# STM32H723 register map
File version: 1.6
CPU: CM7 r0p1, little endian, MPU, FPU, 4 interrupt priority bits
Registers are 32-bit, read-write, reset 0x0 unless marked. A register's access mark holds for its fields unless they carry their own. Offsets are from the block's base; [hi:lo] are bit positions; 'fields as' and 'values as' point back to an identical list.

## OTG1_HS_GLOBAL — USB 1 on the go high speed
Base 0x40040000
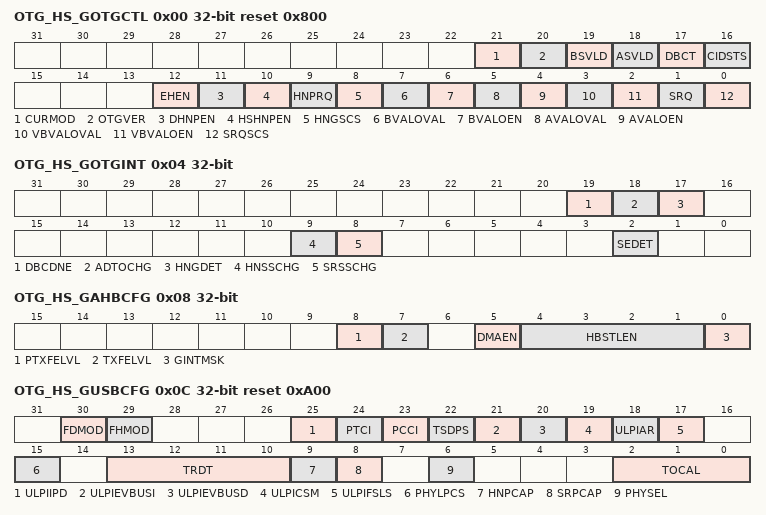
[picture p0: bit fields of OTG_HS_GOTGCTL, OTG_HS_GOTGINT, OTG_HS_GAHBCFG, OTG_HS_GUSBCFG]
0x00 OTG_HS_GOTGCTL access per field reset 0x800 — OTG_HS control and status register
  [21] CURMOD ro — Current mode of operation Indicates the current mode (host or device).
    0=Device mode; 1=Host mode
  [20] OTGVER rw — OTG version Selects the OTG revision.
    0=OTG Version 1.3. OTG1.3 is obsolete for new product development.; 1=OTG Version 2.0. In this version the core supports only data line pulsing for SRP.
  [19] BSVLD ro — B-session valid Indicates the device mode transceiver status. In OTG mode, the user can use this bit to determine if the device is connected or disconnected. Note: Only accessible in device mode.
    0=B-session is not valid; 1=B-session is valid
  [18] ASVLD ro — A-session valid Indicates the host mode transceiver status. Note: Only accessible in host mode.
    0=A-session is not valid; 1=A-session is valid
  [17] DBCT ro — Long/short debounce time Indicates the debounce time of a detected connection. Note: Only accessible in host mode.
    0=Long debounce time, used for physical connections (100 ms + 2.5 Âµs); 1=Short debounce time, used for soft connections (2.5 Âµs)
  [16] CIDSTS ro — Connector ID status Indicates the connector ID status on a connect event. Note: Accessible in both device and host modes.
    0=The OTG_HS controller is in A-device mode; 1=The OTG_HS controller is in B-device mode
  [12] EHEN rw — Embedded host enable It is used to select between OTG A device state machine and embedded host state machine.
    0=OTG A device state machine is selected; 1=Embedded host state machine is selected
  [11] DHNPEN rw — Device HNP enabled The application sets this bit when it successfully receives a SetFeature.SetHNPEnable command from the connected USB host. Note: Only accessible in device mode.
    0=HNP is not enabled in the application; 1=HNP is enabled in the application
  [10] HSHNPEN rw — host set HNP enable The application sets this bit when it has successfully enabled HNP (using the SetFeature.SetHNPEnable command) on the connected device. Note: Only accessible in host mode.
    0=Host Set HNP is not enabled; 1=Host Set HNP is enabled
  [9] HNPRQ rw — HNP request The application sets this bit to initiate an HNP request to the connected USB host. The application can clear this bit by writing a 0 when the host negotiation success status change bit in the OTG_GOTGINT register (HNSSCHG bit in OTG_GOTGINT) is set. The core clears this bit when the HNSSCHG bit is cleared. Note: Only accessible in device mode.
    0=No HNP request; 1=HNP request
  [8] HNGSCS ro — Host negotiation success The core sets this bit when host negotiation is successful. The core clears this bit when the HNP request (HNPRQ) bit in this register is set. Note: Only accessible in device mode.
    0=Host negotiation failure; 1=Host negotiation success
  [7] BVALOVAL rw — B-peripheral session valid override value. This bit is used to set override value for Bvalid signal when BVALOEN bit is set. Note: Only accessible in device mode.
    0=Bvalid value is '0' when BVALOEN = 1; 1=Bvalid value is '1' when BVALOEN = 1
  [6] BVALOEN rw — B-peripheral session valid override enable. This bit is used to enable/disable the software to override the Bvalid signal using the BVALOVAL bit. Note: Only accessible in device mode.
    0=Override is disabled and Bvalid signal from the respective PHY selected is used internally by the core; 1=Internally Bvalid received from the PHY is overridden with BVALOVAL bit value
  [5] AVALOVAL rw — A-peripheral session valid override value. This bit is used to set override value for Avalid signal when AVALOEN bit is set. Note: Only accessible in host mode.
    0=Avalid value is '0' when AVALOEN = 1; 1=Avalid value is '1' when AVALOEN = 1
  [4] AVALOEN rw — A-peripheral session valid override enable. This bit is used to enable/disable the software to override the Avalid signal using the AVALOVAL bit. Note: Only accessible in host mode.
    0=Override is disabled and Avalid signal from the respective PHY selected is used internally by the core; 1=Internally Avalid received from the PHY is overridden with AVALOVAL bit value
  [3] VBVALOVAL rw — VBUS valid override value. This bit is used to set override value for vbusvalid signal when VBVALOEN bit is set. Note: Only accessible in host mode.
    0=vbusvalid value is '0' when VBVALOEN = 1; 1=vbusvalid value is '1' when VBVALOEN = 1
  [2] VBVALOEN rw — VBUS valid override enable. This bit is used to enable/disable the software to override the vbusvalid signal using the VBVALOVAL bit. Note: Only accessible in host mode.
    0=Override is disabled and vbusvalid signal from the respective PHY selected is used internally by the core; 1=Internally vbusvalid received from the PHY is overridden with VBVALOVAL bit value
  [1] SRQ rw — Session request The application sets this bit to initiate a session request on the USB. The application can clear this bit by writing a 0 when the host negotiation success status change bit in the OTG_GOTGINT register (HNSSCHG bit in OTG_GOTGINT) is set. The core clears this bit when the HNSSCHG bit is cleared. If the user uses the USB 1.1 full-speed serial transceiver interface to initiate the session request, the application must wait until VBUS discharges to 0.2 V, after the B-session valid bit in this register (BSVLD bit in OTG_GOTGCTL) is cleared. Note: Only accessible in device mode.
    0=No session request; 1=Session request
  [0] SRQSCS ro — Session request success The core sets this bit when a session request initiation is successful. Note: Only accessible in device mode.
    0=Session request failure; 1=Session request success
0x04 OTG_HS_GOTGINT — OTG_HS interrupt register
  [19] DBCDNE — Debounce done
  [18] ADTOCHG — A-device timeout change
  [17] HNGDET — Host negotiation detected
  [9] HNSSCHG — Host negotiation success status change
  [8] SRSSCHG — Session request success status change
  [2] SEDET — Session end detected
0x08 OTG_HS_GAHBCFG — OTG_HS AHB configuration register
  [8] PTXFELVL — Periodic TxFIFO empty level
  [7] TXFELVL — TxFIFO empty level
  [5] DMAEN — DMA enable
  [4:1] HBSTLEN — Burst length/type
  [0] GINTMSK — Global interrupt mask
0x0C OTG_HS_GUSBCFG access per field reset 0xA00 — OTG_HS USB configuration register
  [30] FDMOD rw — Forced peripheral mode
  [29] FHMOD rw — Forced host mode
  [25] ULPIIPD rw — ULPI interface protect disable
  [24] PTCI rw — Indicator pass through
  [23] PCCI rw — Indicator complement
  [22] TSDPS rw — TermSel DLine pulsing selection
  [21] ULPIEVBUSI rw — ULPI external VBUS indicator
  [20] ULPIEVBUSD rw — ULPI External VBUS Drive
  [19] ULPICSM rw — ULPI Clock SuspendM
  [18] ULPIAR rw — ULPI Auto-resume
  [17] ULPIFSLS rw — ULPI FS/LS select
  [15] PHYLPCS rw — PHY Low-power clock select
  [13:10] TRDT rw — USB turnaround time
  [9] HNPCAP rw — HNP-capable
  [8] SRPCAP rw — SRP-capable
  [6] PHYSEL wo — USB 2.0 high-speed ULPI PHY or USB 1.1 full-speed serial transceiver select
  [2:0] TOCAL rw — FS timeout calibration
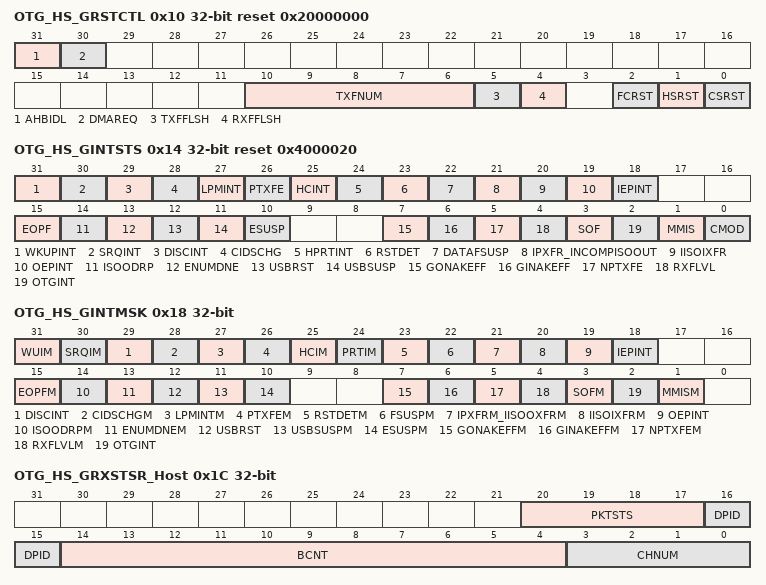
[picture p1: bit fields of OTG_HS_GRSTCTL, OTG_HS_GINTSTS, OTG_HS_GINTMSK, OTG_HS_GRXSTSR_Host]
0x10 OTG_HS_GRSTCTL access per field reset 0x20000000 — OTG_HS reset register
  [31] AHBIDL ro — AHB master idle
  [30] DMAREQ ro — DMA request signal enabled for USB OTG HS
  [10:6] TXFNUM rw — TxFIFO number
  [5] TXFFLSH rw — TxFIFO flush
  [4] RXFFLSH rw — RxFIFO flush
  [2] FCRST rw — Host frame counter reset
  [1] HSRST rw — HCLK soft reset
  [0] CSRST rw — Core soft reset
0x14 OTG_HS_GINTSTS access per field reset 0x4000020 — OTG_HS core interrupt register
  [31] WKUPINT rw — Resume/remote wakeup detected interrupt Wakeup interrupt during suspend(L2) or LPM(L1) state. During suspend(L2): In device mode, this interrupt is asserted when a resume is detected on the USB. In host mode, this interrupt is asserted when a remote wakeup is detected on the USB. During LPM(L1): This interrupt is asserted for either host initiated resume or device initiated remote wakeup on USB. Note: Accessible in both device and host modes.
  [30] SRQINT rw — Session request/new session detected interrupt In host mode, this interrupt is asserted when a session request is detected from the device. In device mode, this interrupt is asserted when VBUS is in the valid range for a B-peripheral device. Accessible in both device and host modes.
  [29] DISCINT rw — Disconnect detected interrupt Asserted when a device disconnect is detected. Note: Only accessible in host mode.
  [28] CIDSCHG rw — Connector ID status change The core sets this bit when there is a change in connector ID status. Note: Accessible in both device and host modes.
  [27] LPMINT rw — LPM interrupt In device mode, this interrupt is asserted when the device receives an LPM transaction and responds with a non-ERRORed response. In host mode, this interrupt is asserted when the device responds to an LPM transaction with a non-ERRORed response or when the host core has completed LPM transactions for the programmed number of times (RETRYCNT bit in OTG_GLPMCFG). This field is valid only if the LPMEN bit in OTG_GLPMCFG is set to 1.
  [26] PTXFE ro — Periodic Tx FIFO empty Asserted when the periodic transmit FIFO is either half or completely empty and there is space for at least one entry to be written in the periodic request queue. The half or completely empty status is determined by the periodic Tx FIFO empty level bit in the OTG_GAHBCFG register (PTXFELVL bit in OTG_GAHBCFG). Note: Only accessible in host mode.
  [25] HCINT ro — Host channels interrupt The core sets this bit to indicate that an interrupt is pending on one of the channels of the core (in host mode). The application must read the OTG_HAINT register to determine the exact number of the channel on which the interrupt occurred, and then read the corresponding OTG_HCINTx register to determine the exact cause of the interrupt. The application must clear the appropriate status bit in the OTG_HCINTx register to clear this bit. Note: Only accessible in host mode.
  [24] HPRTINT ro — Host port interrupt The core sets this bit to indicate a change in port status of one of the OTG_HS controller ports in host mode. The application must read the OTG_HPRT register to determine the exact event that caused this interrupt. The application must clear the appropriate status bit in the OTG_HPRT register to clear this bit. Note: Only accessible in host mode.
  [23] RSTDET rw — Reset detected interrupt In device mode, this interrupt is asserted when a reset is detected on the USB in partial power-down mode when the device is in suspend. Note: Only accessible in device mode.
  [22] DATAFSUSP rw — Data fetch suspended This interrupt is valid only in DMA mode. This interrupt indicates that the core has stopped fetching data for IN endpoints due to the unavailability of TxFIFO space or request queue space. This interrupt is used by the application for an endpoint mismatch algorithm. For example, after detecting an endpoint mismatch, the application: Sets a global nonperiodic IN NAK handshake Disables IN endpoints Flushes the FIFO Determines the token sequence from the IN token sequence learning queue Re-enables the endpoints Clears the global nonperiodic IN NAK handshake If the global nonperiodic IN NAK is cleared, the core has not yet fetched data for the IN endpoint, and the IN token is received: the core generates an âIN token received when FIFO emptyâ interrupt. The OTG then sends a NAK response to the host. To avoid this scenario, the application can check the FetSusp interrupt in OTG_GINTSTS, which ensures that the FIFO is full before clearing a global NAK handshake. Alternatively, the application can mask the âIN token received when FIFO emptyâ interrupt when clearing a global IN NAK handshake.
  [21] IPXFR_INCOMPISOOUT rw
  [20] IISOIXFR rw — Incomplete isochronous IN transfer The core sets this interrupt to indicate that there is at least one isochronous IN endpoint on which the transfer is not completed in the current frame. This interrupt is asserted along with the End of periodic frame interrupt (EOPF) bit in this register. Note: Only accessible in device mode.
  [19] OEPINT ro — OUT endpoint interrupt The core sets this bit to indicate that an interrupt is pending on one of the OUT endpoints of the core (in device mode). The application must read the OTG_DAINT register to determine the exact number of the OUT endpoint on which the interrupt occurred, and then read the corresponding OTG_DOEPINTx register to determine the exact cause of the interrupt. The application must clear the appropriate status bit in the corresponding OTG_DOEPINTx register to clear this bit. Note: Only accessible in device mode.
  [18] IEPINT ro — IN endpoint interrupt The core sets this bit to indicate that an interrupt is pending on one of the IN endpoints of the core (in device mode). The application must read the OTG_DAINT register to determine the exact number of the IN endpoint on which the interrupt occurred, and then read the corresponding OTG_DIEPINTx register to determine the exact cause of the interrupt. The application must clear the appropriate status bit in the corresponding OTG_DIEPINTx register to clear this bit. Note: Only accessible in device mode.
  [15] EOPF rw — End of periodic frame interrupt Indicates that the period specified in the periodic frame interval field of the OTG_DCFG register (PFIVL bit in OTG_DCFG) has been reached in the current frame. Note: Only accessible in device mode.
  [14] ISOODRP rw — Isochronous OUT packet dropped interrupt The core sets this bit when it fails to write an isochronous OUT packet into the Rx FIFO because the Rx FIFO does not have enough space to accommodate a maximum size packet for the isochronous OUT endpoint. Note: Only accessible in device mode.
  [13] ENUMDNE rw — Enumeration done The core sets this bit to indicate that speed enumeration is complete. The application must read the OTG_DSTS register to obtain the enumerated speed. Note: Only accessible in device mode.
  [12] USBRST rw — USB reset The core sets this bit to indicate that a reset is detected on the USB. Note: Only accessible in device mode.
  [11] USBSUSP rw — USB suspend The core sets this bit to indicate that a suspend was detected on the USB. The core enters the suspended state when there is no activity on the data lines for an extended period of time. Note: Only accessible in device mode.
  [10] ESUSP rw — Early suspend The core sets this bit to indicate that an Idle state has been detected on the USB for 3 ms. Note: Only accessible in device mode.
  [7] GONAKEFF ro — Global OUT NAK effective Indicates that the Set global OUT NAK bit in the OTG_DCTL register (SGONAK bit in OTG_DCTL), set by the application, has taken effect in the core. This bit can be cleared by writing the Clear global OUT NAK bit in the OTG_DCTL register (CGONAK bit in OTG_DCTL). Note: Only accessible in device mode.
  [6] GINAKEFF ro — Global IN non-periodic NAK effective Indicates that the Set global non-periodic IN NAK bit in the OTG_DCTL register (SGINAK bit in OTG_DCTL), set by the application, has taken effect in the core. That is, the core has sampled the Global IN NAK bit set by the application. This bit can be cleared by clearing the Clear global non-periodic IN NAK bit in the OTG_DCTL register (CGINAK bit in OTG_DCTL). This interrupt does not necessarily mean that a NAK handshake is sent out on the USB. The STALL bit takes precedence over the NAK bit. Note: Only accessible in device mode.
  [5] NPTXFE ro — Non-periodic Tx FIFO empty This interrupt is asserted when the non-periodic Tx FIFO is either half or completely empty, and there is space for at least one entry to be written to the non-periodic transmit request queue. The half or completely empty status is determined by the non-periodic Tx FIFO empty level bit in the OTG_GAHBCFG register (TXFELVL bit in OTG_GAHBCFG). Note: Accessible in host mode only.
  [4] RXFLVL ro — Rx FIFO non-empty Indicates that there is at least one packet pending to be read from the Rx FIFO. Note: Accessible in both host and device modes.
  [3] SOF rw — Start of frame In host mode, the core sets this bit to indicate that an SOF (FS), or Keep-Alive (LS) is transmitted on the USB. The application must write a 1 to this bit to clear the interrupt. In device mode, in the core sets this bit to indicate that an SOF token has been received on the USB. The application can read the OTG_DSTS register to get the current frame number. This interrupt is seen only when the core is operating in FS. Note: This register may return '1' if read immediately after power on reset. If the register bit reads '1' immediately after power on reset it does not indicate that an SOF has been sent (in case of host mode) or SOF has been received (in case of device mode). The read value of this interrupt is valid only after a valid connection between host and device is established. If the bit is set after power on reset the application can clear the bit. Note: Accessible in both host and device modes.
  [2] OTGINT ro — OTG interrupt The core sets this bit to indicate an OTG protocol event. The application must read the OTG interrupt status (OTG_GOTGINT) register to determine the exact event that caused this interrupt. The application must clear the appropriate status bit in the OTG_GOTGINT register to clear this bit. Note: Accessible in both host and device modes.
  [1] MMIS rw — Mode mismatch interrupt The core sets this bit when the application is trying to access: A host mode register, when the core is operating in device mode A device mode register, when the core is operating in host mode The register access is completed on the AHB with an OKAY response, but is ignored by the core internally and does not affect the operation of the core. Note: Accessible in both host and device modes.
  [0] CMOD ro — Current mode of operation Indicates the current mode. Note: Accessible in both host and device modes.
    0=Device mode; 1=Host mode
0x18 OTG_HS_GINTMSK access per field — OTG_HS interrupt mask register
  [31] WUIM rw — Resume/remote wakeup detected interrupt mask Note: Accessible in both host and device modes.
    0=Masked interrupt; 1=Unmasked interrupt
  [30] SRQIM rw — Session request/new session detected interrupt mask Note: Accessible in both host and device modes.
    0=Masked interrupt; 1=Unmasked interrupt
  [29] DISCINT rw — Disconnect detected interrupt mask Note: Only accessible in host mode.
    0=Masked interrupt; 1=Unmasked interrupt
  [28] CIDSCHGM rw — Connector ID status change mask Note: Accessible in both host and device modes.
    0=Masked interrupt; 1=Unmasked interrupt
  [27] LPMINTM rw — LPM interrupt mask Note: Accessible in both host and device modes.
    0=Masked interrupt; 1=Unmasked interrupt
  [26] PTXFEM rw — Periodic Tx FIFO empty mask Note: Only accessible in host mode.
    0=Masked interrupt; 1=Unmasked interrupt
  [25] HCIM rw — Host channels interrupt mask Note: Only accessible in host mode.
    0=Masked interrupt; 1=Unmasked interrupt
  [24] PRTIM ro — Host port interrupt mask Note: Only accessible in host mode.
    0=Masked interrupt; 1=Unmasked interrupt
  [23] RSTDETM rw — Reset detected interrupt mask Note: Only accessible in device mode.
    0=Masked interrupt; 1=Unmasked interrupt
  [22] FSUSPM rw — Data fetch suspended mask Only accessible in peripheral mode.
    0=Masked interrupt; 1=Unmasked interrupt
  [21] IPXFRM_IISOOXFRM rw
  [20] IISOIXFRM rw — Incomplete isochronous IN transfer mask Note: Only accessible in device mode.
    0=Masked interrupt; 1=Unmasked interrupt
  [19] OEPINT rw — OUT endpoints interrupt mask Note: Only accessible in device mode.
    0=Masked interrupt; 1=Unmasked interrupt
  [18] IEPINT rw — IN endpoints interrupt mask Note: Only accessible in device mode.
    0=Masked interrupt; 1=Unmasked interrupt
  [15] EOPFM rw — End of periodic frame interrupt mask Note: Only accessible in device mode.
    0=Masked interrupt; 1=Unmasked interrupt
  [14] ISOODRPM rw — Isochronous OUT packet dropped interrupt mask Note: Only accessible in device mode.
    0=Masked interrupt; 1=Unmasked interrupt
  [13] ENUMDNEM rw — Enumeration done mask Note: Only accessible in device mode.
    0=Masked interrupt; 1=Unmasked interrupt
  [12] USBRST rw — USB reset mask Note: Only accessible in device mode.
    0=Masked interrupt; 1=Unmasked interrupt
  [11] USBSUSPM rw — USB suspend mask Note: Only accessible in device mode.
    0=Masked interrupt; 1=Unmasked interrupt
  [10] ESUSPM rw — Early suspend mask Note: Only accessible in device mode.
    0=Masked interrupt; 1=Unmasked interrupt
  [7] GONAKEFFM rw — Global OUT NAK effective mask Note: Only accessible in device mode.
    0=Masked interrupt; 1=Unmasked interrupt
  [6] GINAKEFFM rw — Global non-periodic IN NAK effective mask Note: Only accessible in device mode.
    0=Masked interrupt; 1=Unmasked interrupt
  [5] NPTXFEM rw — Non-periodic Tx FIFO empty mask Note: Only accessible in host mode.
    0=Masked interrupt; 1=Unmasked interrupt
  [4] RXFLVLM rw — Receive FIFO non-empty mask Note: Accessible in both device and host modes.
    0=Masked interrupt; 1=Unmasked interrupt
  [3] SOFM rw — Start of frame mask Note: Accessible in both device and host modes.
    0=Masked interrupt; 1=Unmasked interrupt
  [2] OTGINT rw — OTG interrupt mask Note: Accessible in both device and host modes.
    0=Masked interrupt; 1=Unmasked interrupt
  [1] MMISM rw — Mode mismatch interrupt mask Note: Accessible in both device and host modes.
    0=Masked interrupt; 1=Unmasked interrupt
0x1C OTG_HS_GRXSTSR_Host ro — OTG_HS Receive status debug read register (host mode)
  [20:17] PKTSTS — Packet status
  [16:15] DPID — Data PID
  [14:4] BCNT — Byte count
  [3:0] CHNUM — Channel number
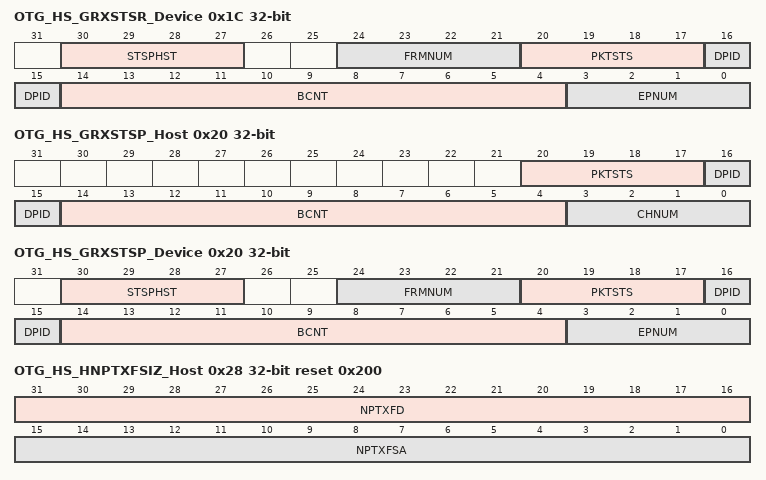
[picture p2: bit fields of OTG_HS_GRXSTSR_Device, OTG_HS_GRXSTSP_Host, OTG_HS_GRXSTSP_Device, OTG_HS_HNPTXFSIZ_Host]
0x1C OTG_HS_GRXSTSR_Device ro (alternate view of OTG_HS_GRXSTSR_Host) — OTG_HS Receive status debug read register (peripheral mode mode)
  [30:27] STSPHST — Frame number
  [24:21] FRMNUM — Frame number
  [20:17] PKTSTS — Packet status
  [16:15] DPID — Data PID
  [14:4] BCNT — Byte count
  [3:0] EPNUM — Endpoint number
0x20 OTG_HS_GRXSTSP_Host ro — OTG_HS status read and pop register (host mode)
  fields as OTG_HS_GRXSTSR_Host
0x20 OTG_HS_GRXSTSP_Device ro (alternate view of OTG_HS_GRXSTSP_Host) — OTG_HS status read and pop register (peripheral mode)
  fields as OTG_HS_GRXSTSR_Device
0x24 OTG_HS_GRXFSIZ reset 0x200 — OTG_HS Receive FIFO size register
  [15:0] RXFD — RxFIFO depth
0x28 OTG_HS_HNPTXFSIZ_Host reset 0x200 — OTG_HS nonperiodic transmit FIFO size register (host mode)
  [31:16] NPTXFD — Nonperiodic TxFIFO depth
  [15:0] NPTXFSA — Nonperiodic transmit RAM start address
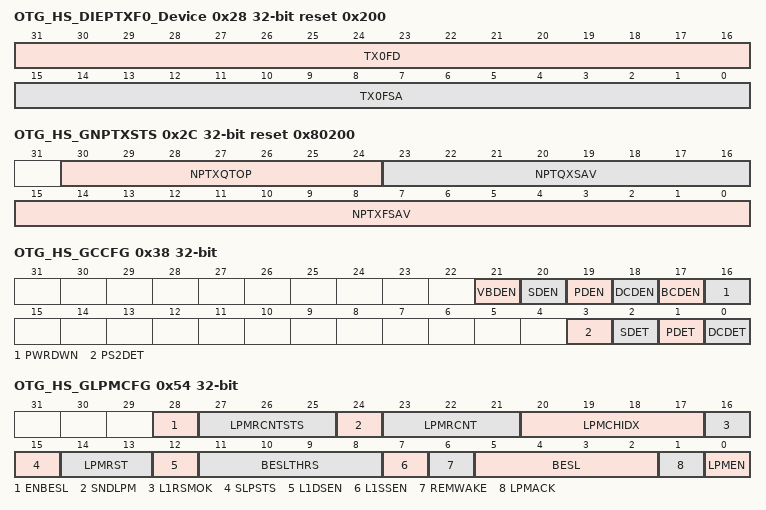
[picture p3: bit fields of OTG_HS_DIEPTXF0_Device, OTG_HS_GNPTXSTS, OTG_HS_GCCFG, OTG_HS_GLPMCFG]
0x28 OTG_HS_DIEPTXF0_Device reset 0x200 (alternate view of OTG_HS_HNPTXFSIZ_Host) — Endpoint 0 transmit FIFO size (peripheral mode)
  [31:16] TX0FD — Endpoint 0 TxFIFO depth
  [15:0] TX0FSA — Endpoint 0 transmit RAM start address
0x2C OTG_HS_GNPTXSTS ro reset 0x80200 — OTG_HS nonperiodic transmit FIFO/queue status register
  [30:24] NPTXQTOP — Top of the nonperiodic transmit request queue
  [23:16] NPTQXSAV — Nonperiodic transmit request queue space available
  [15:0] NPTXFSAV — Nonperiodic TxFIFO space available
0x38 OTG_HS_GCCFG — OTG_HS general core configuration register
  [21] VBDEN — USB VBUS detection enable
  [20] SDEN — Secondary detection (SD) mode enable
  [19] PDEN — Primary detection (PD) mode enable
  [18] DCDEN — Data contact detection (DCD) mode enable
  [17] BCDEN — Battery charging detector (BCD) enable
  [16] PWRDWN — Power down
  [3] PS2DET — DM pull-up detection status
  [2] SDET — Secondary detection (SD) status
  [1] PDET — Primary detection (PD) status
  [0] DCDET — Data contact detection (DCD) status
0x3C OTG_HS_CID reset 0x1200 — OTG_HS core ID register
  [31:0] PRODUCT_ID
0x54 OTG_HS_GLPMCFG access per field — OTG core LPM configuration register
  [28] ENBESL rw — Enable best effort service latency
  [27:25] LPMRCNTSTS ro — LPM retry count status
  [24] SNDLPM rw — Send LPM transaction
  [23:21] LPMRCNT rw — LPM retry count
  [20:17] LPMCHIDX rw — LPM Channel Index
  [16] L1RSMOK ro — Sleep State Resume OK
  [15] SLPSTS ro — Port sleep status
  [14:13] LPMRST ro — LPM response
  [12] L1DSEN rw — L1 deep sleep enable
  [11:8] BESLTHRS rw — BESL threshold
  [7] L1SSEN rw — L1 Shallow Sleep enable
  [6] REMWAKE ro — bRemoteWake value
  [5:2] BESL ro — Best effort service latency
  [1] LPMACK rw — LPM token acknowledge enable
  [0] LPMEN rw — LPM support enable
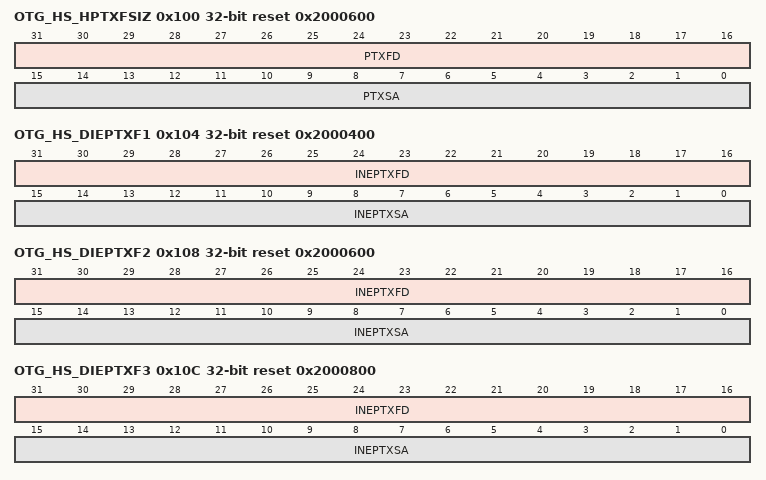
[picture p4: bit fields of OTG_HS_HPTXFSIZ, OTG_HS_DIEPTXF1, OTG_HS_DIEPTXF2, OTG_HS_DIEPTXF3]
0x100 OTG_HS_HPTXFSIZ reset 0x2000600 — OTG_HS Host periodic transmit FIFO size register
  [31:16] PTXFD — Host periodic TxFIFO depth
  [15:0] PTXSA — Host periodic TxFIFO start address
0x104 OTG_HS_DIEPTXF1 reset 0x2000400 — OTG_HS device IN endpoint transmit FIFO size register
  [31:16] INEPTXFD — IN endpoint TxFIFO depth
  [15:0] INEPTXSA — IN endpoint FIFOx transmit RAM start address
0x108 OTG_HS_DIEPTXF2 reset 0x2000600 — OTG_HS device IN endpoint transmit FIFO size register
  fields as OTG_HS_DIEPTXF1
0x10C OTG_HS_DIEPTXF3 reset 0x2000800 — OTG_HS device IN endpoint transmit FIFO size register
  fields as OTG_HS_DIEPTXF1
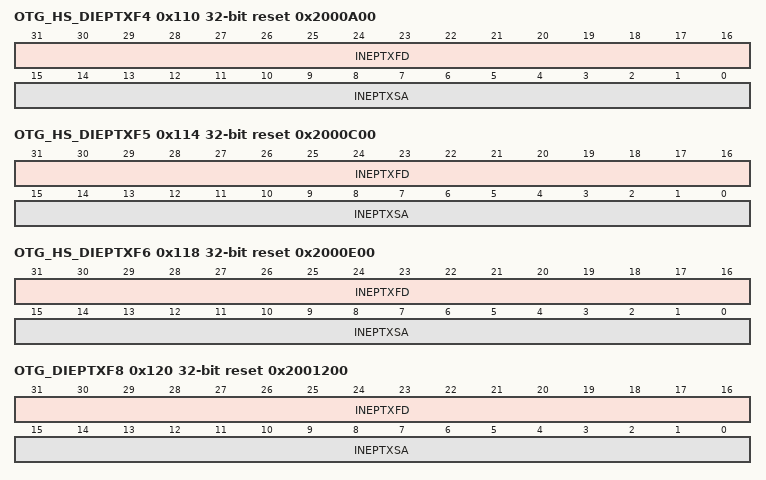
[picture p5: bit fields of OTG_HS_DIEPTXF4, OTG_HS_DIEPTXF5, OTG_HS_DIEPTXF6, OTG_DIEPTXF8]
0x110 OTG_HS_DIEPTXF4 reset 0x2000A00 — OTG_HS device IN endpoint transmit FIFO size register
  fields as OTG_HS_DIEPTXF1
0x114 OTG_HS_DIEPTXF5 reset 0x2000C00 — OTG_HS device IN endpoint transmit FIFO size register
  fields as OTG_HS_DIEPTXF1
0x118 OTG_HS_DIEPTXF6 reset 0x2000E00 — OTG_HS device IN endpoint transmit FIFO size register
  fields as OTG_HS_DIEPTXF1
0x120 OTG_DIEPTXF8 reset 0x2001200
  [31:16] INEPTXFD — IN endpoint Tx FIFO depth This value is in terms of 32-bit words. Minimum value is 16
  [15:0] INEPTXSA — IN endpoint FIFOx transmit RAM start address This field contains the memory start address for IN endpoint transmit FIFOx. The address must be aligned with a 32-bit memory location.
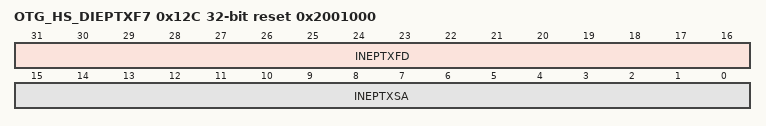
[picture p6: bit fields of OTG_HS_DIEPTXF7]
0x12C OTG_HS_DIEPTXF7 reset 0x2001000 — OTG_HS device IN endpoint transmit FIFO size register
  fields as OTG_HS_DIEPTXF1
